# HC32M413 register map
File version: 1.0
CPU: CM4 r0p1, little endian, MPU, FPU, 4 interrupt priority bits
Registers are 32-bit, read-write, reset 0x0 unless marked. A register's access mark holds for its fields unless they carry their own. Offsets are from the block's base; lines under a group give offsets from that group; [hi:lo] are bit positions; {n}, {i} and the like mark numbered series; 'fields as' and 'values as' point back to an identical list; <NAME> marks a mode.

## Memory map
0x00020000 ICG size 0x14
0x40010400 EFM size 0x289
0x40010800 AOS size 0x40
0x40015000 TMRA1 size 0x146 — desc TMRA
0x40015400 TMRA2 size 0x146 — desc TMRA
0x40015800 TMRA3 size 0x146 — desc TMRA
0x40015C00 TMRA4 size 0x146 — desc TMRA
0x40016000 TMRA5 size 0x182
0x40017000 TMR4 size 0x11E
0x40017C00 EMB0 size 0x1C — desc EMB
0x40017C20 EMB1 size 0x1C — desc EMB
0x4001C000 SPI size 0x1C
0x4001D000 USART1 size 0x1C — desc USART
0x4001D400 USART2 size 0x20 — desc USART
0x4001E800 HALL size 0x34
0x40021000 USART3 size 0x20 — desc USART
0x40021400 USART4 size 0x20 — desc USART
0x40024000 TMR01 size 0x18 — desc TMR0
0x40024400 TMR02 size 0x18 — desc TMR0
0x40030000 ADC size 0xC4
0x40048400 FCM size 0x24
0x40049000 WDT size 0xC
0x40049400 SWDT size 0xC
0x4004A000 CMP1 size 0x20 — desc CMP
0x4004A000 CMP_COMMON size 0x10
0x4004A100 CMP2 size 0x20 — desc CMP
0x4004A400 CMP3 size 0x20 — desc CMP
0x4004E000 I2C size 0x3C
0x40050400 CRC size 0x100
0x40051000 INTC size 0x2AC
0x40052000 DCU size 0x1C
0x40053000 DMA size 0x138
0x40053800 GPIO size 0x5CC
0x40054000 PWC size 0x54
0x40054100 RMU size 0x8
0x40054400 CMU size 0x49
0x40054800 MAU size 0x2C
0x40054C00 PERIC size 0x20
0xE0042000 DBGC size 0x40

## Interrupts
{n} GLOBAL{n}_SWINT{n} (INTC) (n=0..15) — global interrupt {n} or software interrupt {n}
{n+16} EXTINT{n}_SWINT{n+16} (INTC) (n=0..7) — external interrupt {n} or software interrupt {n+16}
25 DMA_TC0_BTC0 (DMA) — DMA_TC0_BTC0 interrupt
26 DMA_TC1_BTC1 (DMA) — DMA_TC1_BTC1 interrupt
27 DMA_TC2_BTC2 (DMA) — DMA_TC2_BTC2 interrupt
28 DMA_TC3_BTC3 (DMA) — DMA_TC3_BTC3 interrupt
29 PEERR_RDCOL (EFM) — EFM program erase error or read column interrupt
30 OPTEND (EFM) — EFM Operation End interrupt
31 DCU — DCU interrupt
32 FPU_ERR (INTC) — FPU error interrupt
33 MAU — MAU interrupt
34 TMR0_1 (TMR01) — TMR0_1 interrupt
35 TMR0_2 (TMR02) — TMR0_2 interrupt
36 XTAL_STOP (CMU) — Xtal stop interrupt
37 SWDT — SWDT interrupt
38 TMRA_1_OVF_UDF (TMRA1) — TMRA_1_OVF_UDF interrupt
39 TMRA_1_CMP (TMRA1) — TMRA_1_CMP interrupt
40 TMRA_2_OVF_UDF (TMRA2) — TMRA_2_OVF_UDF interrupt
41 TMRA_2_CMP (TMRA2) — TMRA_2_CMP interrupt
42 TMRA_3_OVF_UDF (TMRA3) — TMRA_3_OVF_UDF interrupt
43 TMRA_3_CMP (TMRA3) — TMRA_3_CMP interrupt
44 TMRA_4_OVF_UDF (TMRA4) — TMRA_4_OVF_UDF interrupt
45 TMRA_4_CMP (TMRA4) — TMRA_4_CMP interrupt
46 EMB_GR0 (EMB0) — EMB_GR0 interrupt
47 EMB_GR1 (EMB1) — EMB_GR1 interrupt
48 TMR4_GCMP (TMR4) — TMR4_GCMP interrupt
49 TMR4_OVF_UDF (TMR4) — TMR4_OVF_UDF interrupt
50 TMR4_RELOAD (TMR4) — TMR4_RELOAD interrupt
52 USART1 — USART1 interrupt
54 SPI — SPI interrupt
55 TMRA_5_OVF_UDF (TMRA5) — TMRA_5_OVF_UDF interrupt
56 TMRA_5_CMP (TMRA5) — TMRA_5_CMP interrupt
57 USART2 — USART2 interrupt
59 USART3 — USART3 interrupt
61 USART4 — USART4 interrupt
63 HALL — HALL interrupt
64 CMP1 — CMP1 interrupt
65 CMP2 — CMP2 interrupt
66 CMP3 — CMP3 interrupt
67 I2C — I2C interrupt
69 LVD1 (PWC) — LVD1 interrupt
70 LVD2 (PWC) — LVD2 interrupt
71 FCM — FCM interrupt
72 WDT — WDT interrupt
73 ADC — ADC interrupt

## ADC
Base 0x40030000
0x00 STR 8-bit
  [0] STRT
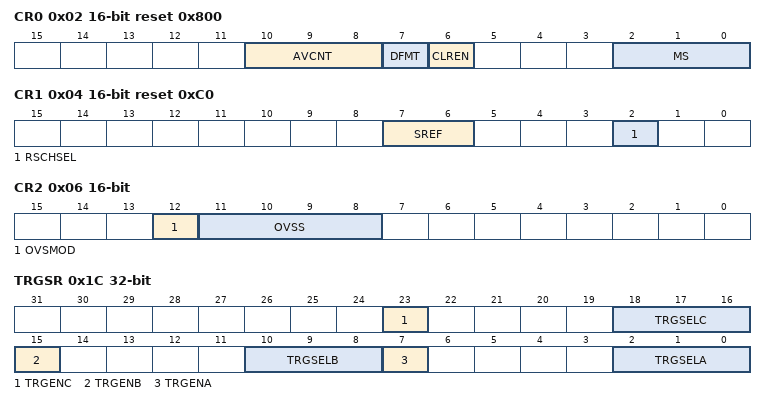
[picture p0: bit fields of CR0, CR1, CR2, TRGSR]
0x02 CR0 16-bit reset 0x800
  [10:8] AVCNT, [7] DFMT, [6] CLREN, [2:0] MS
0x04 CR1 16-bit reset 0xC0
  [7:6] SREF, [2] RSCHSEL
0x06 CR2 16-bit
  [12] OVSMOD, [11:8] OVSS
0x0C CHSELRA
  [15:0] CHSELA
0x10 CHSELRB
  [15:0] CHSELB
0x14 AVCHSELR
  [15:0] AVCHSEL
0x1C TRGSR
  [23] TRGENC, [18:16] TRGSELC, [15] TRGENB, [10:8] TRGSELB, [7] TRGENA, [2:0] TRGSELA
{0x20+i} SSTR{i} 8-bit reset 0x4 (i=0..15)
0x40 CHSELRC
  [15:0] CHSELC
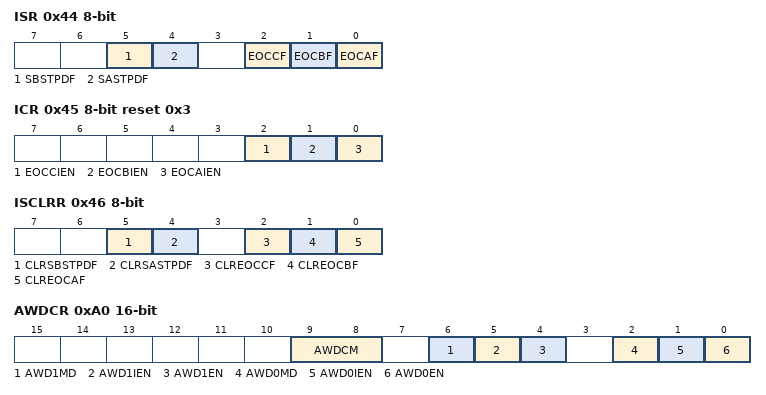
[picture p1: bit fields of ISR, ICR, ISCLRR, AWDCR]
0x44 ISR 8-bit ro
  [5] SBSTPDF, [4] SASTPDF, [2] EOCCF, [1] EOCBF, [0] EOCAF
0x45 ICR 8-bit reset 0x3
  [2] EOCCIEN, [1] EOCBIEN, [0] EOCAIEN
0x46 ISCLRR 8-bit wo
  [5] CLRSBSTPDF, [4] CLRSASTPDF, [2] CLREOCCF, [1] CLREOCBF, [0] CLREOCAF
{0x50+2i} DR{i} 16-bit ro (i=0..15)
0xA0 AWDCR 16-bit
  [9:8] AWDCM, [6] AWD1MD, [5] AWD1IEN, [4] AWD1EN, [2] AWD0MD, [1] AWD0IEN, [0] AWD0EN
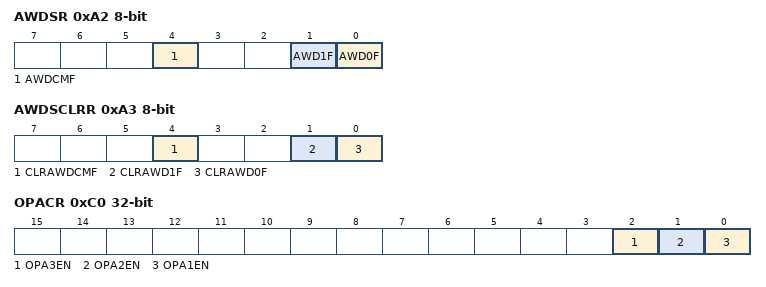
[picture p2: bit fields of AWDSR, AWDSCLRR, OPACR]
0xA2 AWDSR 8-bit ro
  [4] AWDCMF, [1] AWD1F, [0] AWD0F
0xA3 AWDSCLRR 8-bit
  [4] CLRAWDCMF, [1] CLRAWD1F, [0] CLRAWD0F
0xA4 AWD0DR0 16-bit
0xA6 AWD0DR1 16-bit reset 0xFFFF
0xA8 AWD0CHSR 8-bit
  [4:0] AWDCH
0xAC AWD1DR0 16-bit
0xAE AWD1DR1 16-bit reset 0xFFFF
0xB0 AWD1CHSR 8-bit
  [4:0] AWDCH
0xC0 OPACR
  [2] OPA3EN, [1] OPA2EN, [0] OPA1EN
